VERSION "hoverboard-amr-1"

NS_ :

BS_:

BU_: PI HOVERBOARD BODY

BO_ 16 ESTOP: 1 PI
 SG_ estop : 0|1@1+ (1,0) [0|1] "" HOVERBOARD,BODY

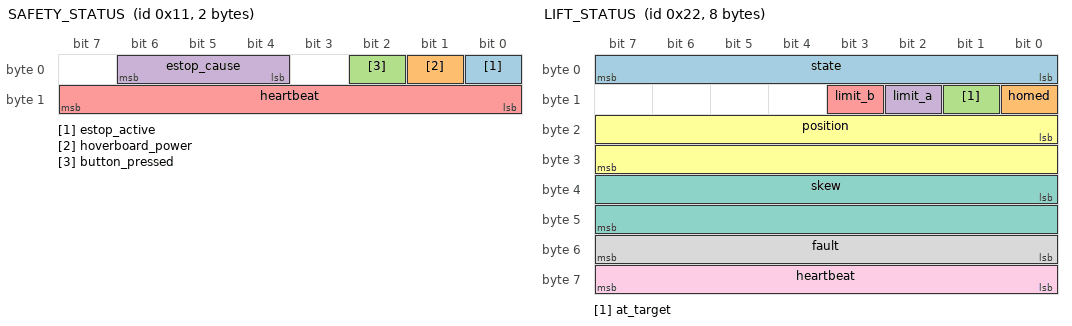
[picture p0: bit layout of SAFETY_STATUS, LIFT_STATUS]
BO_ 17 SAFETY_STATUS: 2 BODY
 SG_ estop_active : 0|1@1+ (1,0) [0|1] "" PI
 SG_ hoverboard_power : 1|1@1+ (1,0) [0|1] "" PI
 SG_ button_pressed : 2|1@1+ (1,0) [0|1] "" PI
 SG_ estop_cause : 4|3@1+ (1,0) [0|7] "" PI
 SG_ heartbeat : 8|8@1+ (1,0) [0|255] "" PI

BO_ 32 BODY_CMD: 2 PI
 SG_ light_mode : 0|8@1+ (1,0) [0|3] "" BODY
 SG_ buzzer : 8|8@1+ (1,0) [0|2] "" BODY

BO_ 33 LIFT_CMD: 3 PI
 SG_ command : 0|8@1+ (1,0) [0|2] "" BODY
 SG_ target : 8|16@1+ (0.1,0) [0|6553.5] "mm" BODY

BO_ 34 LIFT_STATUS: 8 BODY
 SG_ state : 0|8@1+ (1,0) [0|4] "" PI
 SG_ homed : 8|1@1+ (1,0) [0|1] "" PI
 SG_ at_target : 9|1@1+ (1,0) [0|1] "" PI
 SG_ limit_a : 10|1@1+ (1,0) [0|1] "" PI
 SG_ limit_b : 11|1@1+ (1,0) [0|1] "" PI
 SG_ position : 16|16@1- (0.1,0) [-3276.8|3276.7] "mm" PI
 SG_ skew : 32|16@1- (0.1,0) [-3276.8|3276.7] "mm" PI
 SG_ fault : 48|8@1+ (1,0) [0|3] "" PI
 SG_ heartbeat : 56|8@1+ (1,0) [0|255] "" PI

BO_ 513 HB_CMD: 4 PI
 SG_ cmd_left : 0|16@1- (1,0) [-32768|32767] "rpm" HOVERBOARD
 SG_ cmd_right : 16|16@1- (1,0) [-32768|32767] "rpm" HOVERBOARD

BO_ 385 HB_ODOM: 8 HOVERBOARD
 SG_ ticks_left : 0|32@1- (1,0) [-2147483648|2147483647] "ticks" PI
 SG_ ticks_right : 32|32@1- (1,0) [-2147483648|2147483647] "ticks" PI

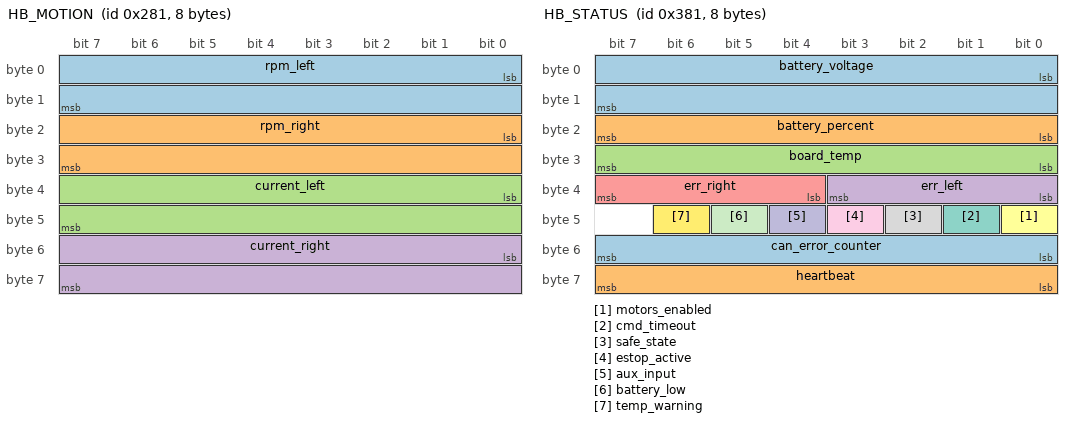
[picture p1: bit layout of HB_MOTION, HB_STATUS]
BO_ 641 HB_MOTION: 8 HOVERBOARD
 SG_ rpm_left : 0|16@1- (1,0) [-32768|32767] "rpm" PI
 SG_ rpm_right : 16|16@1- (1,0) [-32768|32767] "rpm" PI
 SG_ current_left : 32|16@1- (0.01,0) [-327.68|327.67] "A" PI
 SG_ current_right : 48|16@1- (0.01,0) [-327.68|327.67] "A" PI

BO_ 897 HB_STATUS: 8 HOVERBOARD
 SG_ battery_voltage : 0|16@1+ (0.01,0) [0|655.35] "V" PI
 SG_ battery_percent : 16|8@1+ (1,0) [0|100] "%" PI
 SG_ board_temp : 24|8@1- (1,0) [-128|127] "degC" PI
 SG_ err_left : 32|4@1+ (1,0) [0|15] "" PI
 SG_ err_right : 36|4@1+ (1,0) [0|15] "" PI
 SG_ motors_enabled : 40|1@1+ (1,0) [0|1] "" PI
 SG_ cmd_timeout : 41|1@1+ (1,0) [0|1] "" PI
 SG_ safe_state : 42|1@1+ (1,0) [0|1] "" PI
 SG_ estop_active : 43|1@1+ (1,0) [0|1] "" PI
 SG_ aux_input : 44|1@1+ (1,0) [0|1] "" PI
 SG_ battery_low : 45|1@1+ (1,0) [0|1] "" PI
 SG_ temp_warning : 46|1@1+ (1,0) [0|1] "" PI
 SG_ can_error_counter : 48|8@1+ (1,0) [0|255] "" PI
 SG_ heartbeat : 56|8@1+ (1,0) [0|255] "" PI

CM_ "Hoverboard mainboard (VARIANT_CAN) protocol. IDs shown for CAN_NODE_ID = 1: CMD 0x200+n, ODOM 0x180+n, MOTION 0x280+n, STATUS 0x380+n. All wheel values: positive = robot moves forward.";
CM_ BU_ PI "Raspberry Pi 5 host (ROS 2).";
CM_ BU_ HOVERBOARD "Hoverboard mainboard STM32F103RC, hoverboard-firmware-hack VARIANT_CAN.";
CM_ BU_ BODY "STM32F411CEU6 body controller: e-stop authority (its relay switches the hoverboard board's power through the ON SWITCH connector), stack light, buzzer and the lift (two motors with encoders).";
CM_ BO_ 16 "E-stop broadcast. 1 = stop (latched), 0 = release. Hoverboard: active braking to 0 rpm. BODY: latches the e-stop and opens the hoverboard power relay once the wheels are braked; on release closes it (refused while the button is pressed). BODY also sends ESTOP=1 itself when its button is pressed.";
CM_ BO_ 17 "E-stop controller state, 10 Hz and immediately on change. BODY also trips the e-stop if no HB_CMD frame is seen for 500 ms (host watchdog).";
CM_ SG_ 17 hoverboard_power "1 = relay closed, hoverboard board powered.";
CM_ SG_ 17 button_pressed "Physical e-stop button currently pressed.";
CM_ SG_ 17 estop_cause "Cause of the active or last e-stop.";
CM_ BO_ 32 "Stack light and buzzer request, 5 Hz. Ignored while the e-stop is latched (red blinks, 3 beeps on the trip). No frame for 1 s: green blinks (BODY alive, waiting for the Pi).";
CM_ SG_ 32 light_mode "idle: green. moving: green + blinking amber. paused: amber. fault: red.";
CM_ SG_ 32 buzzer "slow: one short beep per second (travel alarm). fast: 5 Hz beeping (lifting, warning).";
CM_ BO_ 33 "Lift command. goto: height above the home switches; the first goto after power-up homes first. home: run down to the limit switches and zero there (clears a fault). Send on change; goto may be repeated.";
CM_ BO_ 34 "Lift state, 10 Hz and immediately on a state change. Two motors with encoders; outputs are off while the e-stop is latched.";
CM_ SG_ 34 position "Mean of the left and right sides, 0 before homing.";
CM_ SG_ 34 skew "Left minus right.";
CM_ BO_ 513 "Wheel speed command, send at 50 Hz. SPD_MODE: rpm, clamped to N_MOT_MAX. VLT/TRQ mode: normalized -1000..1000. No frame for 200 ms (CAN_TIMEOUT): motors de-energized (unless the e-stop is latched: then the board keeps braking).";
CM_ BO_ 385 "Hall-sensor odometry, 50 Hz. 6 steps per electrical revolution (~90 per wheel revolution on 15 pole-pair hub motors). Counters wrap: use int32 differences. Reset to 0 at board power-on.";
CM_ BO_ 641 "Measured wheel speed and DC link current per motor, 50 Hz. Current averaged over the frame period.";
CM_ BO_ 897 "Status and heartbeat, 10 Hz.";
CM_ SG_ 897 battery_percent "Estimated from Li-ion cell voltage under load (BAT_CELLS cells).";
CM_ SG_ 897 err_left "BLDC controller error code: bit0 hall sensors not connected, bit1 hall sensor short circuit, bit2 motor not running (stall).";
CM_ SG_ 897 err_right "BLDC controller error code: bit0 hall sensors not connected, bit1 hall sensor short circuit, bit2 motor not running (stall).";
CM_ SG_ 897 safe_state "Any input timeout active: motors de-energized (OPEN_MODE).";
CM_ SG_ 897 can_error_counter "max(TEC, REC) of the bxCAN controller. Rising values indicate bit timing / wiring problems.";
CM_ SG_ 897 heartbeat "Increments by 1 per status frame.";
VAL_ 17 estop_cause 0 "none" 1 "host_request" 2 "button" 3 "host_timeout" ;
VAL_ 33 command 0 "stop" 1 "goto" 2 "home" ;
VAL_ 34 state 0 "unhomed" 1 "homing" 2 "idle" 3 "moving" 4 "fault" ;
VAL_ 34 fault 0 "none" 1 "homing_timeout" 2 "stall" 3 "skew" ;
VAL_ 32 light_mode 0 "idle" 1 "moving" 2 "paused" 3 "fault" ;
VAL_ 32 buzzer 0 "off" 1 "slow" 2 "fast" ;
